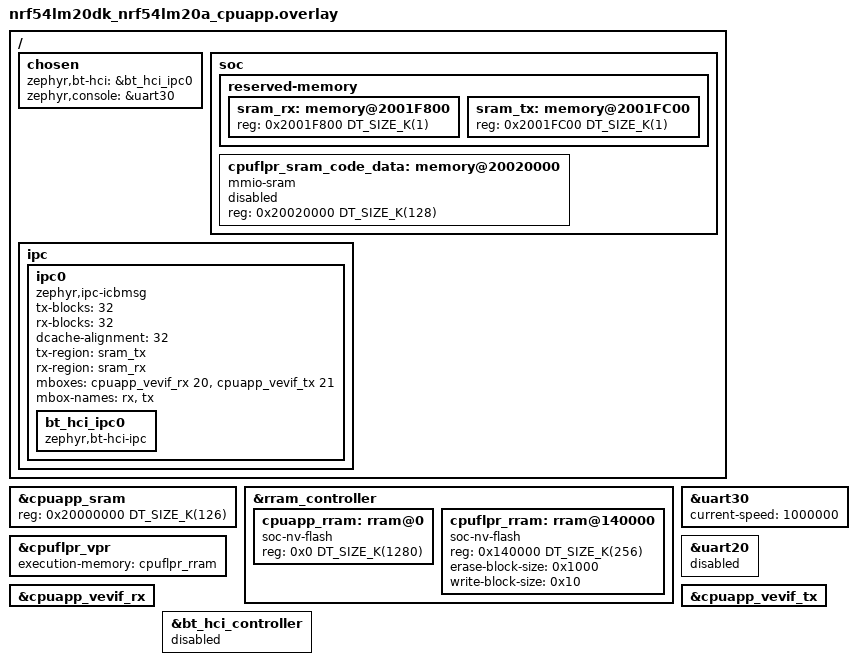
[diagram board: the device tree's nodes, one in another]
/*
 * Copyright (c) 2026 Nordic Semiconductor ASA
 *
 * SPDX-License-Identifier: Apache-2.0
 */

/ {
	chosen {
		zephyr,bt-hci = &bt_hci_ipc0;
		zephyr,console = &uart30;
	};

	soc {
		reserved-memory {
			#address-cells = <1>;
			#size-cells = <1>;

			sram_rx: memory@2001F800 {
				reg = <0x2001F800 DT_SIZE_K(1)>;
			};

			sram_tx: memory@2001FC00 {
				reg = <0x2001FC00 DT_SIZE_K(1)>;
			};
		};

		cpuflpr_sram_code_data: memory@20020000 {
			compatible = "mmio-sram";
			reg = <0x20020000 DT_SIZE_K(128)>;
			ranges = <0x0 0x20020000 DT_SIZE_K(128)>;
			status = "reserved";
			#address-cells = <1>;
			#size-cells = <1>;
		};
	};

	ipc {
		ipc0: ipc0 {
			compatible = "zephyr,ipc-icbmsg";
			tx-blocks = <32>;
			rx-blocks = <32>;
			dcache-alignment = <32>;
			tx-region = <&sram_tx>;
			rx-region = <&sram_rx>;
			mboxes = <&cpuapp_vevif_rx 20>, <&cpuapp_vevif_tx 21>;
			mbox-names = "rx", "tx";
			status = "okay";

			bt_hci_ipc0: bt_hci_ipc0 {
				compatible = "zephyr,bt-hci-ipc";
				status = "okay";
			};
		};
	};
};

&cpuapp_sram {
	reg = <0x20000000 DT_SIZE_K(126)>;
	ranges = <0x0 0x20000000 DT_SIZE_K(126)>;
};

&rram_controller {
	cpuapp_rram: rram@0 {
		compatible = "soc-nv-flash";
		reg = <0x0 DT_SIZE_K(1280)>;
		ranges = <0x0 0 DT_SIZE_K(1280)>;
	};

	cpuflpr_rram: rram@140000 {
		compatible = "soc-nv-flash";
		reg = <0x140000 DT_SIZE_K(256)>;
		ranges = <0x0 0x140000 DT_SIZE_K(256)>;
		erase-block-size = <0x1000>;
		write-block-size = <0x10>;
		#address-cells = <1>;
		#size-cells = <1>;
	};
};

&cpuflpr_vpr {
	status = "okay";
	execution-memory = <&cpuflpr_rram>;
	/*
	 * execution-memory = <&cpuflpr_sram_code_data>;
	 * source-memory = <&cpuflpr_rram>;
	 */
};

&uart30 {
	current-speed = <1000000>;
	status = "okay";
};

&uart20 {
	status = "disabled";
};

&cpuapp_vevif_rx {
	status = "okay";
};

&cpuapp_vevif_tx {
	status = "okay";
};

&bt_hci_controller {
	status = "disabled";
};
